# LPC54S018M register map
Vendor: nxp.com; File version: 1.0
CPU: CM4 r0p1, little endian, MPU, FPU, VTOR, 3 interrupt priority bits
Registers are 32-bit, read-write, reset 0x0 unless marked. A register's access mark holds for its fields unless they carry their own. Offsets are from the block's base; [hi:lo] are bit positions.

## USBFSH — LPC54S60x/LPC5460x USB0 Full-speed Host controller
Base 0x400A2000
0x00 HCREVISION ro reset 0x10 — BCD representation of the version of the HCI specification that is implemented by the Host Controller (HC)
  [7:0] REV — Revision.
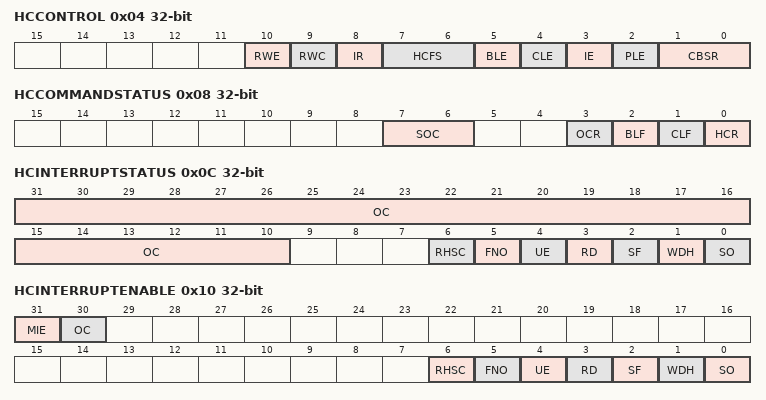
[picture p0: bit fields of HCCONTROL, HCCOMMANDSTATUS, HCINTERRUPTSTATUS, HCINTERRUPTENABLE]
0x04 HCCONTROL — Defines the operating modes of the HC
  [10] RWE — RemoteWakeupEnable This bit is used by HCD to enable or disable the remote wake-up feature upon the detection of upstream resume signaling.
  [9] RWC — RemoteWakeupConnected This bit indicates whether HC supports remote wake-up signaling.
  [8] IR — InterruptRouting This bit determines the routing of interrupts generated by events registered in HcInterruptStatus.
  [7:6] HCFS — HostControllerFunctionalState for USB 00b: USBRESET 01b: USBRESUME 10b: USBOPERATIONAL 11b: USBSUSPEND A transition to USBOPERATIONAL from another state causes SOFgeneration to begin 1 ms later.
  [5] BLE — BulkListEnable This bit is set to enable the processing of the Bulk list in the next Frame.
  [4] CLE — ControlListEnable.
  [3] IE — IsochronousEnable.
  [2] PLE — PeriodicListEnable.
  [1:0] CBSR — ControlBulkServiceRatio.
0x08 HCCOMMANDSTATUS — This register is used to receive the commands from the Host Controller Driver (HCD)
  [7:6] SOC — SchedulingOverrunCount These bits are incremented on each scheduling overrun error.
  [3] OCR — OwnershipChangeRequest This bit is set by an OS HCD to request a change of control of the HC.
  [2] BLF — BulkListFilled This bit is used to indicate whether there are any TDs on the Bulk list.
  [1] CLF — ControlListFilled This bit is used to indicate whether there are any TDs on the Control list.
  [0] HCR — HostControllerReset This bit is set by HCD to initiate a software reset of HC.
0x0C HCINTERRUPTSTATUS — Indicates the status on various events that cause hardware interrupts by setting the appropriate bits
  [31:10] OC — OwnershipChange This bit is set by HC when HCD sets the OwnershipChangeRequest field in HcCommandStatus.
  [6] RHSC — RootHubStatusChange This bit is set when the content of HcRhStatus or the content of any of HcRhPortStatus[NumberofDownstreamPort] has changed.
  [5] FNO — FrameNumberOverflow This bit is set when the MSb of HcFmNumber (bit 15) changes value, from 0 to 1 or from 1 to 0, and after HccaFrameNumber has been updated.
  [4] UE — UnrecoverableError This bit is set when HC detects a system error not related to USB.
  [3] RD — ResumeDetected This bit is set when HC detects that a device on the USB is asserting resume signaling.
  [2] SF — StartofFrame This bit is set by HC at each start of a frame and after the update of HccaFrameNumber.
  [1] WDH — WritebackDoneHead This bit is set immediately after HC has written HcDoneHead to HccaDoneHead.
  [0] SO — SchedulingOverrun This bit is set when the USB schedule for the current Frame overruns and after the update of HccaFrameNumber.
0x10 HCINTERRUPTENABLE — Controls the bits in the HcInterruptStatus register and indicates which events will generate a hardware interrupt
  [31] MIE — Master Interrupt Enable.
  [30] OC — Ownership Change interrupt.
  [6] RHSC — Root Hub Status Change interrupt.
  [5] FNO — Frame Number Overflow interrupt.
  [4] UE — Unrecoverable Error interrupt.
  [3] RD — Resume Detect interrupt.
  [2] SF — Start of Frame interrupt.
  [1] WDH — HcDoneHead Writeback interrupt.
  [0] SO — Scheduling Overrun interrupt.
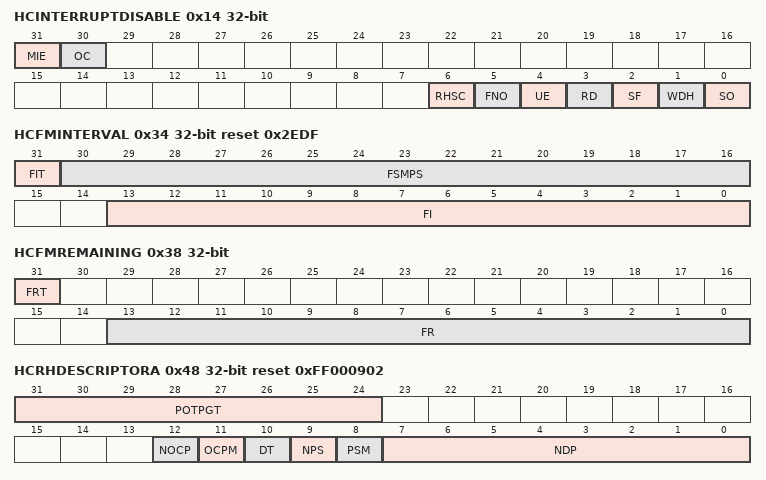
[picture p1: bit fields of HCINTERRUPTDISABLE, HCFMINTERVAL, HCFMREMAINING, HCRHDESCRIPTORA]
0x14 HCINTERRUPTDISABLE — The bits in this register are used to disable corresponding bits in the HCInterruptStatus register and in turn disable that event leading to hardware interrupt
  [31] MIE — A 0 written to this field is ignored by HC.
  [30] OC — Ownership Change interrupt.
  [6] RHSC — Root Hub Status Change interrupt.
  [5] FNO — Frame Number Overflow interrupt.
  [4] UE — Unrecoverable Error interrupt.
  [3] RD — Resume Detect interrupt.
  [2] SF — Start of Frame interrupt.
  [1] WDH — HcDoneHead Writeback interrupt.
  [0] SO — Scheduling Overrun interrupt.
0x18 HCHCCA — Contains the physical address of the host controller communication area
  [31:8] HCCA — Base address of the Host Controller Communication Area.
0x1C HCPERIODCURRENTED — Contains the physical address of the current isochronous or interrupt endpoint descriptor
  [31:4] PCED ro — The content of this register is updated by HC after a periodic ED is processed.
0x20 HCCONTROLHEADED — Contains the physical address of the first endpoint descriptor of the control list
  [31:4] CHED — HC traverses the Control list starting with the HcControlHeadED pointer.
0x24 HCCONTROLCURRENTED — Contains the physical address of the current endpoint descriptor of the control list
  [31:4] CCED — ControlCurrentED.
0x28 HCBULKHEADED — Contains the physical address of the first endpoint descriptor of the bulk list
  [31:4] BHED — BulkHeadED HC traverses the bulk list starting with the HcBulkHeadED pointer.
0x2C HCBULKCURRENTED — Contains the physical address of the current endpoint descriptor of the bulk list
  [31:4] BCED — BulkCurrentED This is advanced to the next ED after the HC has served the current one.
0x30 HCDONEHEAD — Contains the physical address of the last transfer descriptor added to the 'Done' queue
  [31:4] DH ro — DoneHead When a TD is completed, HC writes the content of HcDoneHead to the NextTD field of the TD.
0x34 HCFMINTERVAL reset 0x2EDF — Defines the bit time interval in a frame and the full speed maximum packet size which would not cause an overrun
  [31] FIT — FrameIntervalToggle HCD toggles this bit whenever it loads a new value to FrameInterval.
  [30:16] FSMPS — FSLargestDataPacket This field specifies a value which is loaded into the Largest Data Packet Counter at the beginning of each frame.
  [13:0] FI — FrameInterval This specifies the interval between two consecutive SOFs in bit times.
0x38 HCFMREMAINING — A 14-bit counter showing the bit time remaining in the current frame
  [31] FRT ro — FrameRemainingToggle This bit is loaded from the FrameIntervalToggle field of HcFmInterval whenever FrameRemaining reaches 0.
  [13:0] FR ro — FrameRemaining This counter is decremented at each bit time.
0x3C HCFMNUMBER — Contains a 16-bit counter and provides the timing reference among events happening in the HC and the HCD
  [15:0] FN ro — FrameNumber This is incremented when HcFmRemaining is re-loaded.
0x40 HCPERIODICSTART — Contains a programmable 14-bit value which determines the earliest time HC should start processing a periodic list
  [13:0] PS — PeriodicStart After a hardware reset, this field is cleared and then set by HCD during the HC initialization.
0x44 HCLSTHRESHOLD reset 0x628 — Contains 11-bit value which is used by the HC to determine whether to commit to transfer a maximum of 8-byte LS packet before EOF
  [11:0] LST — LSThreshold This field contains a value which is compared to the FrameRemaining field prior to initiating a Low Speed transaction.
0x48 HCRHDESCRIPTORA reset 0xFF000902 — First of the two registers which describes the characteristics of the root hub
  [31:24] POTPGT — PowerOnToPowerGoodTime This byte specifies the duration the HCD has to wait before accessing a powered-on port of the root hub.
  [12] NOCP — NoOverCurrentProtection This bit describes how the overcurrent status for the root hub ports are reported.
  [11] OCPM — OverCurrentProtectionMode This bit describes how the overcurrent status for the root hub ports are reported.
  [10] DT — DeviceType This bit specifies that the root hub is not a compound device.
  [9] NPS — NoPowerSwitching These bits are used to specify whether power switching is supported or port are always powered.
  [8] PSM — PowerSwitchingMode This bit is used to specify how the power switching of the root hub ports is controlled.
  [7:0] NDP — NumberDownstreamPorts These bits specify the number of downstream ports supported by the root hub.
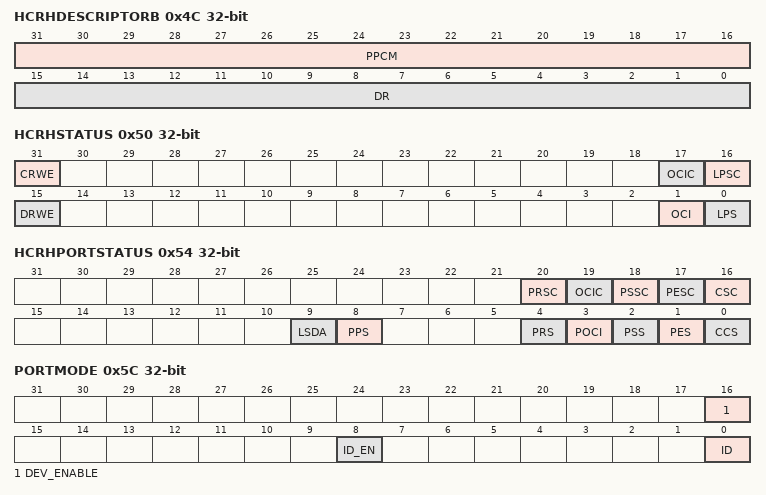
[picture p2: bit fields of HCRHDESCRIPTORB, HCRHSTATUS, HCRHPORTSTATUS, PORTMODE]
0x4C HCRHDESCRIPTORB (reset mask 0x3FFFFFFF) — Second of the two registers which describes the characteristics of the Root Hub
  [31:16] PPCM — PortPowerControlMask Each bit indicates if a port is affected by a global power control command when PowerSwitchingMode is set.
  [15:0] DR — DeviceRemovable Each bit is dedicated to a port of the Root Hub.
0x50 HCRHSTATUS — This register is divided into two parts
  [31] CRWE — (write) ClearRemoteWakeupEnable Writing a 1 clears DeviceRemoveWakeupEnable.
  [17] OCIC — OverCurrentIndicatorChange This bit is set by hardware when a change has occurred to the OCI field of this register.
  [16] LPSC — (read) LocalPowerStatusChange The root hub does not support the local power status feature.
  [15] DRWE — (read) DeviceRemoteWakeupEnable This bit enables a ConnectStatusChange bit as a resume event, causing a USBSUSPEND to USBRESUME state transition and setting the ResumeDetected interrupt.
  [1] OCI — OverCurrentIndicator This bit reports overcurrent conditions when the global reporting is implemented.
  [0] LPS — (read) LocalPowerStatus The Root Hub does not support the local power status feature; thus, this bit is always read as 0.
0x54 HCRHPORTSTATUS — Controls and reports the port events on a per-port basis
  [20] PRSC — PortResetStatusChange This bit is set at the end of the 10 ms port reset signal.
  [19] OCIC — PortOverCurrentIndicatorChange This bit is valid only if overcurrent conditions are reported on a per-port basis.
  [18] PSSC — PortSuspendStatusChange This bit is set when the full resume sequence is completed.
  [17] PESC — PortEnableStatusChange This bit is set when hardware events cause the PortEnableStatus bit to be cleared.
  [16] CSC — ConnectStatusChange This bit is set whenever a connect or disconnect event occurs.
  [9] LSDA — (read) LowSpeedDeviceAttached This bit indicates the speed of the device attached to this port.
  [8] PPS — (read) PortPowerStatus This bit reflects the porta's power status, regardless of the type of power switching implemented.
  [4] PRS — (read) PortResetStatus When this bit is set by a write to SetPortReset, port reset signaling is asserted.
  [3] POCI — (read) PortOverCurrentIndicator This bit is only valid when the Root Hub is configured in such a way that overcurrent conditions are reported on a per-port basis.
  [2] PSS — (read) PortSuspendStatus This bit indicates the port is suspended or in the resume sequence.
  [1] PES — (read) PortEnableStatus This bit indicates whether the port is enabled or disabled.
  [0] CCS — (read) CurrentConnectStatus This bit reflects the current state of the downstream port.
0x5C PORTMODE — Controls the port if it is attached to the host block or the device block
  [16] DEV_ENABLE — 1: device 0: host.
  [8] ID_EN — Port ID pin pull-up enable.
  [0] ID — Port ID pin value.
